# DSS_EDP0_V2A_S_CORE_VP_REGS_SAPB register map
Vendor: Texas Instruments
Peripheral module from a debugger description file (folder J721S2).
Registers are 32-bit, access not given, reset 0x0 unless marked. A register's access mark holds for its fields unless they carry their own. Offsets are as the file gives them; lines under a group give offsets from that group; [hi:lo] are bit positions; {n}, {i} and the like mark numbered series; 'fields as' and 'values as' point back to an identical list; <NAME> marks a mode.

## DSS_EDP0_V2A_S_CORE_VP_REGS_SAPB
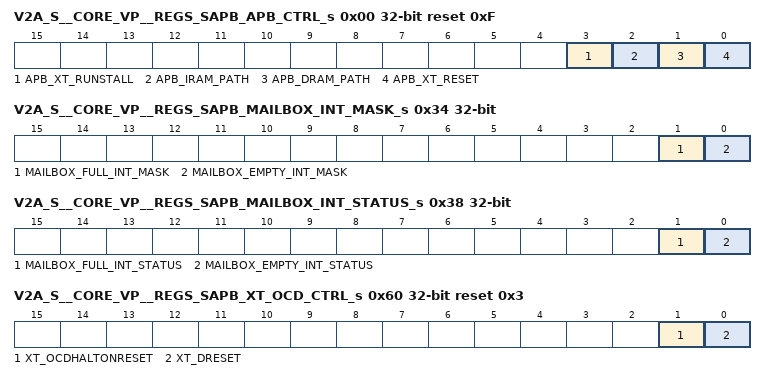
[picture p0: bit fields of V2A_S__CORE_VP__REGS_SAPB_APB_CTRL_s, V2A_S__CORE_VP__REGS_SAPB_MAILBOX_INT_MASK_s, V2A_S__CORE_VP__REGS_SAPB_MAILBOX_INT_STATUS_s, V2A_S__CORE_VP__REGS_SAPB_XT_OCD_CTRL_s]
0x00 V2A_S__CORE_VP__REGS_SAPB_APB_CTRL_s reset 0xF — APB control register (SAPB)
  [3] APB_XT_RUNSTALL rw — Not used
  [2] APB_IRAM_PATH rw — Not used
  [1] APB_DRAM_PATH rw — Not used
  [0] APB_XT_RESET rw — Not used
0x04 V2A_S__CORE_VP__REGS_SAPB_xt_int_ctrl_s — Internal CPU Interrupt Polarity Control Register.
  [1:0] XT_INT_POLARITY rw — Not used
0x08 V2A_S__CORE_VP__REGS_SAPB_MAILBOX_FULL_ADDR_s — Mailbox full indication status register. This register provides a status of the mailbox that is used to send messages from the Host processor to internal uCPU. Mailbox full flag can be a source of mailbox interrupt.
  [0] MAILBOX_FULL ro — Mailbox full indication. 0x1-mailbox full. No more messages can be sent to mailbox 0x0-mailbox not-full. At least 1 write can be performed to mailbox
0x0C V2A_S__CORE_VP__REGS_SAPB_MAILBOX_EMPTY_ADDR_s reset 0x1 — Mailbox empty indication status register. This register provides a status of the mailbox that is used to send responses from the internal uCPU to host processor as a result of previously sent message. Mailbox empty flag can be a source of not-empty mailbox interrupt.
  [0] MAILBOX_EMPTY ro — Mailbox Empty indication 0x1-mailbox empty. No response available 0x0-mailbox not-empty. There is at least 1 byte of a response in mailbox available to read by Host processor
0x10 V2A_S__CORE_VP__REGS_SAPB_mailbox0_wr_data_s — Mailbox write data register
  [7:0] MAILBOX0_WR_DATA rw — Mailbox write Data.
0x14 V2A_S__CORE_VP__REGS_SAPB_mailbox0_rd_data_s — Mailbox Read data register
  [7:0] MAILBOX0_RD_DATA ro — Mailbox Read data
0x18 V2A_S__CORE_VP__REGS_SAPB_KEEP_ALIVE_s — Software keep alive counter
  [7:0] KEEP_ALIVE_CNT ro — Software keep alive counter. Counter is initialized to 0x0 after reset and incremented by 0x1 with every FW kernel loop. It can be used to determine if internal CPU started running correctly.
0x1C V2A_S__CORE_VP__REGS_SAPB_VER_L_s — Software Version Register.
  [7:0] VER_LSB ro — Software Version lower byte. Loaded by Firmware at the beggining of firmware operation.
0x20 V2A_S__CORE_VP__REGS_SAPB_VER_H_s — Software Version Register.
  [7:0] VER_MSB ro — Software Version higher byte. Loaded by Firmware at the beggining of firmware operation.
0x24 V2A_S__CORE_VP__REGS_SAPB_VER_LIB_L_ADDR_s — Software Library Version Register.
  [7:0] SW_LIB_VER_L ro — Software Library Version lower byte. Loaded by Firmware at the beggining of firmware operation.
0x28 V2A_S__CORE_VP__REGS_SAPB_VER_LIB_H_ADDR_s — Software Library Version Register.
  [7:0] SW_LIB_VER_H ro — Software Library Version higher byte. Loaded by Firmware at the beggining of firmware operation.
0x2C V2A_S__CORE_VP__REGS_SAPB_SW_DEBUG_L_s — Software/Firmware Debug Register.
  [7:0] SW_DEBUG_7_0 ro — Register used for debug purposes [lower byte]. Can be written internally by firmware to allow Core Driver to read the internal status. Not used during normal operation since it requires a special version of firmware with a debug capabilities.
0x30 V2A_S__CORE_VP__REGS_SAPB_SW_DEBUG_H_s — Software/Firmware Debug Register.
  [7:0] SW_DEBUG_15_8 ro — Register used for debug purposes [higher byte]. Can be written internally by firmware to allow Core Driver to read the internal status. Not used during normal operation since it requires a special version of firmware with a debug capabilities.
0x34 V2A_S__CORE_VP__REGS_SAPB_MAILBOX_INT_MASK_s — Mailbox Interrupt mask register
  [1] MAILBOX_FULL_INT_MASK rw — Mailbox Full Interrupt mask 0x0-interrupt enabled 0x1-interrupt disabled
  [0] MAILBOX_EMPTY_INT_MASK rw — Mailbox Not-empty Interrupt mask 0x0-interrupt enabled 0x1-interrupt disabled
0x38 V2A_S__CORE_VP__REGS_SAPB_MAILBOX_INT_STATUS_s — Mailbox Interrupt Status register
  [1] MAILBOX_FULL_INT_STATUS ro — Mailbox full interrupt. Active HIGH. Cleared on read. This interrupt is set when mailbox becomes full which means there is no more space for messages sent from Host processor to internal uCPU and when this interrupt is enabled in MAILBOX_INT_MASK_p register. It is set when mailbox_full bit transitions from 0 to 1.
  [0] MAILBOX_EMPTY_INT_STATUS ro — Mailbox not-empty interrupt. Active HIGH. Cleared on read. This interrupt is set when mailbox becomes not-empty which means there is a response in the mailbox available to read by the Host processer and when interrupt is enabled in MAILBOX_INT_MASK_p register. It is set when mailbox_empty bit transitions from 1 to 0.
0x3C V2A_S__CORE_VP__REGS_SAPB_SW_CLK_L_s — Core Clock frequency
  [7:0] SW_CLOCK_VAL_L rw — Not used.
0x40 V2A_S__CORE_VP__REGS_SAPB_SW_CLK_H_s reset 0x64 — Core Clock frequency
  [7:0] SW_CLOCK_VAL_H rw — Not used.
{0x44+4i} V2A_S__CORE_VP__REGS_SAPB_SW_EVENTS{i}_s (i=0..3) — Not used. 0x0 when read.
  [7:0] SW_EVENTS{8i+7}_{8i} ro
0x60 V2A_S__CORE_VP__REGS_SAPB_XT_OCD_CTRL_s reset 0x3 — Internal CPU - On Chip Debug (OCD) Ctrl Register
  [1] XT_OCDHALTONRESET rw — Not used
  [0] XT_DRESET rw — Not used
0x64 V2A_S__CORE_VP__REGS_SAPB_XT_OCD_CTRL_RO_s — Internal CPU - OCD R0 mode configuration
  [0] XT_XOCDMODE ro — Internal CPU - OCD mode configuration
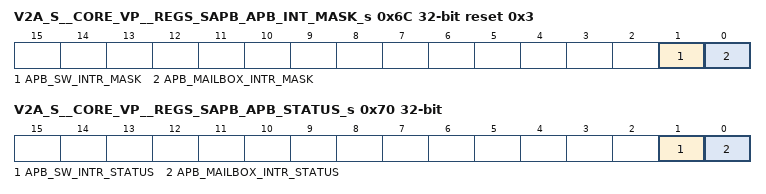
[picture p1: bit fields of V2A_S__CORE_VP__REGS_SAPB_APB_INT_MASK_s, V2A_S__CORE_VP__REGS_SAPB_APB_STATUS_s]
0x6C V2A_S__CORE_VP__REGS_SAPB_APB_INT_MASK_s reset 0x3 — APB Interrupt Mask Register
  [1] APB_SW_INTR_MASK rw — Not used.
  [0] APB_MAILBOX_INTR_MASK rw — Mailbox Interrupt mask 0x0-interrupt enabled 0x1-interrupt disabled
0x70 V2A_S__CORE_VP__REGS_SAPB_APB_STATUS_s — APB interrupt status register
  [1] APB_SW_INTR_STATUS ro — Not used.
  [0] APB_MAILBOX_INTR_STATUS ro — Mailbox Interrupt status. Active HIGH. If this bit is set further status should be read from MAILBOX_INT_STATUS register. This bit is cleared automatically on read from MAILBOX_INT_STATUS register.
